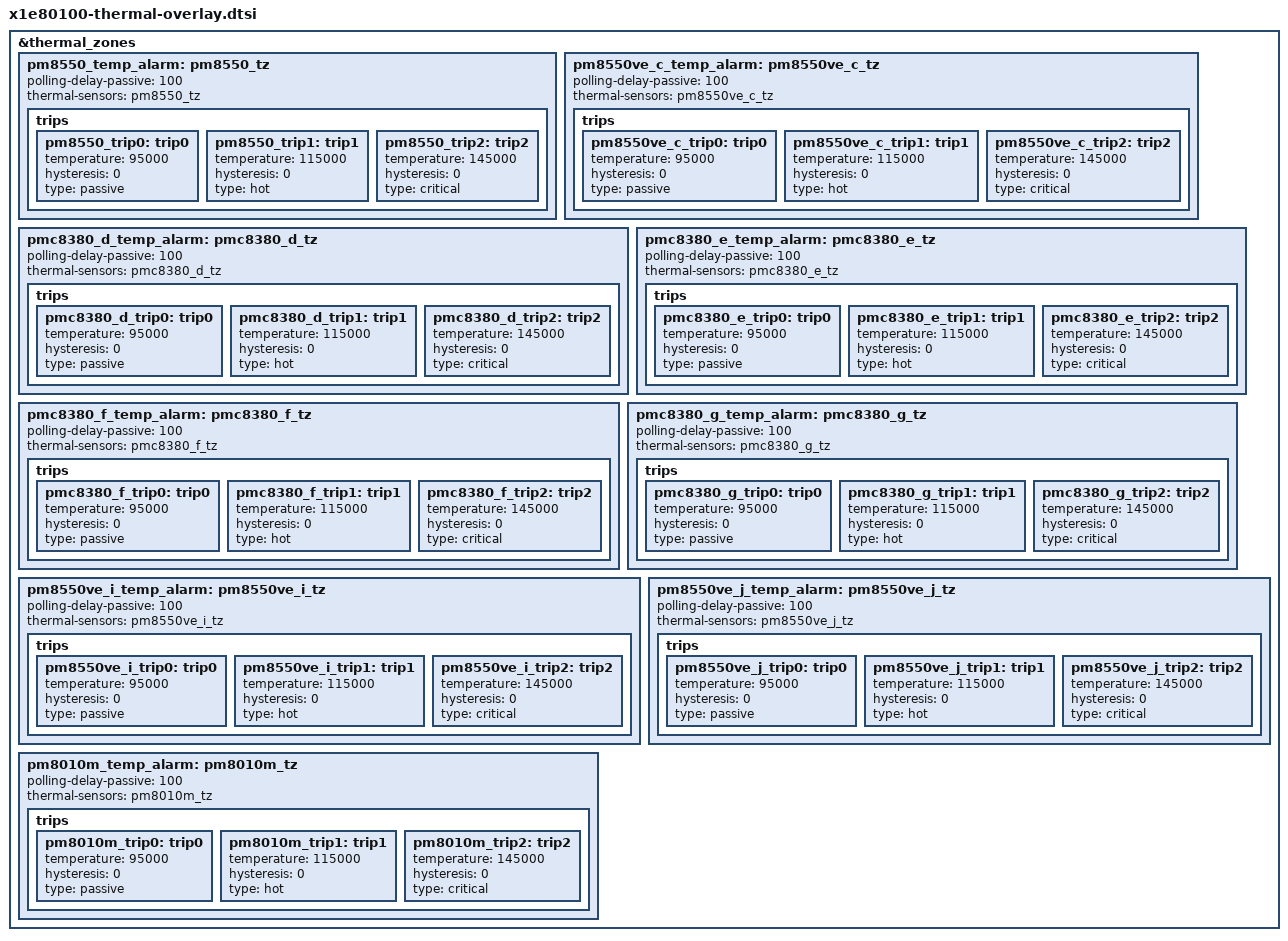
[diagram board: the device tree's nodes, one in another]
// SPDX-License-Identifier: BSD-3-Clause
/*
 * Copyright (c) Qualcomm Technologies, Inc. and/or its subsidiaries.
 */

&thermal_zones {
	pm8550_temp_alarm: pm8550_tz {
		polling-delay-passive = <100>;
		thermal-sensors = <&pm8550_tz>;

		trips {
			pm8550_trip0: trip0 {
				temperature = <95000>;
				hysteresis = <0>;
				type = "passive";
			};

			pm8550_trip1: trip1 {
				temperature = <115000>;
				hysteresis = <0>;
				type = "hot";
			};

			pm8550_trip2: trip2 {
				temperature = <145000>;
				hysteresis = <0>;
				type = "critical";
			};
		};
	};

	pm8550ve_c_temp_alarm: pm8550ve_c_tz {
		polling-delay-passive = <100>;
		thermal-sensors = <&pm8550ve_c_tz>;

		trips {
			pm8550ve_c_trip0: trip0 {
				temperature = <95000>;
				hysteresis = <0>;
				type = "passive";
			};

			pm8550ve_c_trip1: trip1 {
				temperature = <115000>;
				hysteresis = <0>;
				type = "hot";
			};

			pm8550ve_c_trip2: trip2 {
				temperature = <145000>;
				hysteresis = <0>;
				type = "critical";
			};
			};
		};

	pmc8380_d_temp_alarm: pmc8380_d_tz {
		polling-delay-passive = <100>;
		thermal-sensors = <&pmc8380_d_tz>;

		trips {
			pmc8380_d_trip0: trip0 {
				temperature = <95000>;
				hysteresis = <0>;
				type = "passive";
			};

			pmc8380_d_trip1: trip1 {
				temperature = <115000>;
				hysteresis = <0>;
				type = "hot";
			};

			pmc8380_d_trip2: trip2 {
				temperature = <145000>;
				hysteresis = <0>;
				type = "critical";
			};
		};
	};

	pmc8380_e_temp_alarm: pmc8380_e_tz {
		polling-delay-passive = <100>;
		thermal-sensors = <&pmc8380_e_tz>;

		trips {
			pmc8380_e_trip0: trip0 {
				temperature = <95000>;
				hysteresis = <0>;
				type = "passive";
			};

			pmc8380_e_trip1: trip1 {
				temperature = <115000>;
				hysteresis = <0>;
				type = "hot";
			};

			pmc8380_e_trip2: trip2 {
				temperature = <145000>;
				hysteresis = <0>;
				type = "critical";
			};
		};
	};

	pmc8380_f_temp_alarm: pmc8380_f_tz {
		polling-delay-passive = <100>;
		thermal-sensors = <&pmc8380_f_tz>;

		trips {
			pmc8380_f_trip0: trip0 {
				temperature = <95000>;
				hysteresis = <0>;
				type = "passive";
			};

			pmc8380_f_trip1: trip1 {
				temperature = <115000>;
				hysteresis = <0>;
				type = "hot";
			};

			pmc8380_f_trip2: trip2 {
				temperature = <145000>;
				hysteresis = <0>;
				type = "critical";
			};
		};
	};

	pmc8380_g_temp_alarm: pmc8380_g_tz {
		polling-delay-passive = <100>;
		thermal-sensors = <&pmc8380_g_tz>;

		trips {
			pmc8380_g_trip0: trip0 {
				temperature = <95000>;
				hysteresis = <0>;
				type = "passive";
			};

			pmc8380_g_trip1: trip1 {
				temperature = <115000>;
				hysteresis = <0>;
				type = "hot";
			};

			pmc8380_g_trip2: trip2 {
				temperature = <145000>;
				hysteresis = <0>;
				type = "critical";
			};
		};
	};

	pm8550ve_i_temp_alarm: pm8550ve_i_tz {
		polling-delay-passive = <100>;
		thermal-sensors = <&pm8550ve_i_tz>;

		trips {
			pm8550ve_i_trip0: trip0 {
				temperature = <95000>;
				hysteresis = <0>;
				type = "passive";
			};

			pm8550ve_i_trip1: trip1 {
				temperature = <115000>;
				hysteresis = <0>;
				type = "hot";
			};

			pm8550ve_i_trip2: trip2 {
				temperature = <145000>;
				hysteresis = <0>;
				type = "critical";
			};
		};
	};

	pm8550ve_j_temp_alarm: pm8550ve_j_tz {
		polling-delay-passive = <100>;
		thermal-sensors = <&pm8550ve_j_tz>;

		trips {
			pm8550ve_j_trip0: trip0 {
				temperature = <95000>;
				hysteresis = <0>;
				type = "passive";
			};

			pm8550ve_j_trip1: trip1 {
				temperature = <115000>;
				hysteresis = <0>;
				type = "hot";
			};

			pm8550ve_j_trip2: trip2 {
				temperature = <145000>;
				hysteresis = <0>;
				type = "critical";
			};
		};
	};

	pm8010m_temp_alarm: pm8010m_tz {
		polling-delay-passive = <100>;
		thermal-sensors = <&pm8010m_tz>;

		trips {
			pm8010m_trip0: trip0 {
				temperature = <95000>;
				hysteresis = <0>;
				type = "passive";
			};

			pm8010m_trip1: trip1 {
				temperature = <115000>;
				hysteresis = <0>;
				type = "hot";
			};

			pm8010m_trip2: trip2 {
				temperature = <145000>;
				hysteresis = <0>;
				type = "critical";
			};
		};
	};
};
